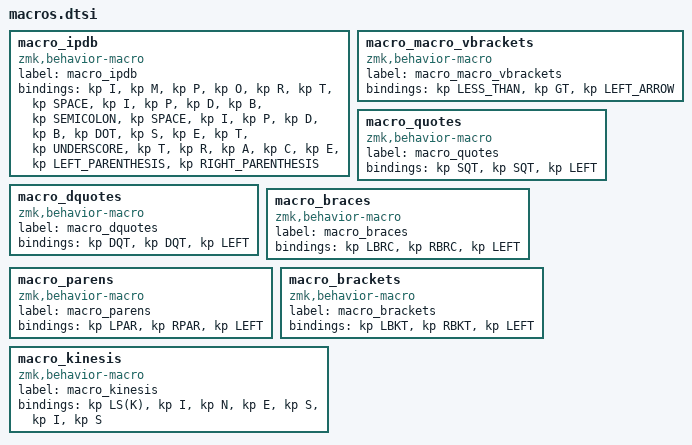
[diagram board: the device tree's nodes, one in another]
macro_ipdb: macro_ipdb{
compatible = "zmk,behavior-macro";
label = "macro_ipdb";
#binding-cells = <0>;
bindings = <&kp I>, <&kp M>, <&kp P>, <&kp O>, <&kp R>, <&kp T>, <&kp SPACE>, <&kp I>, <&kp P>, <&kp D>, <&kp B>, <&kp SEMICOLON>, <&kp SPACE>, <&kp I>, <&kp P>, <&kp D>, <&kp B>, <&kp DOT>, <&kp S>, <&kp E>, <&kp T>, <&kp UNDERSCORE>, <&kp T>, <&kp R>, <&kp A>, <&kp C>, <&kp E>, <&kp LEFT_PARENTHESIS>, <&kp RIGHT_PARENTHESIS>;
};
macro_macro_vbrackets: macro_macro_vbrackets{
compatible = "zmk,behavior-macro";
label = "macro_macro_vbrackets";
#binding-cells = <0>;
bindings = <&kp LESS_THAN>, <&kp GT>, <&kp LEFT_ARROW>;
};
macro_quotes: macro_quotes{
compatible = "zmk,behavior-macro";
label = "macro_quotes";
#binding-cells = <0>;
bindings = <&kp SQT>, <&kp SQT>, <&kp LEFT>;
};
macro_dquotes: macro_dquotes{
compatible = "zmk,behavior-macro";
label = "macro_dquotes";
#binding-cells = <0>;
bindings = <&kp DQT>, <&kp DQT>, <&kp LEFT>;
};
macro_braces: macro_braces{
compatible = "zmk,behavior-macro";
label = "macro_braces";
#binding-cells = <0>;
bindings = <&kp LBRC>, <&kp RBRC>, <&kp LEFT>;
};
macro_parens: macro_parens{
compatible = "zmk,behavior-macro";
label = "macro_parens";
#binding-cells = <0>;
bindings = <&kp LPAR>, <&kp RPAR>, <&kp LEFT>;
};
macro_brackets: macro_brackets{
compatible = "zmk,behavior-macro";
label = "macro_brackets";
#binding-cells = <0>;
bindings = <&kp LBKT>, <&kp RBKT>, <&kp LEFT>;
};
macro_kinesis: macro_kinesis{
compatible = "zmk,behavior-macro";
label = "macro_kinesis";
#binding-cells = <0>;
bindings = <&kp LS(K)>, <&kp I>, <&kp N>, <&kp E>, <&kp S>, <&kp I>, <&kp S>;
};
